# RSL15 register map
Vendor: ONSemiconductor; Series: RSL15 Series; File version: 1.0
CPU: CM33 r0p4, little endian, MPU, FPU, 3 interrupt priority bits
Registers are 32-bit, read-write, reset 0x0 unless marked. A register's access mark holds for its fields unless they carry their own. Offsets are from the block's base; [hi:lo] are bit positions.

## BBIF — Baseband Controller Interface
Base 0x40001800
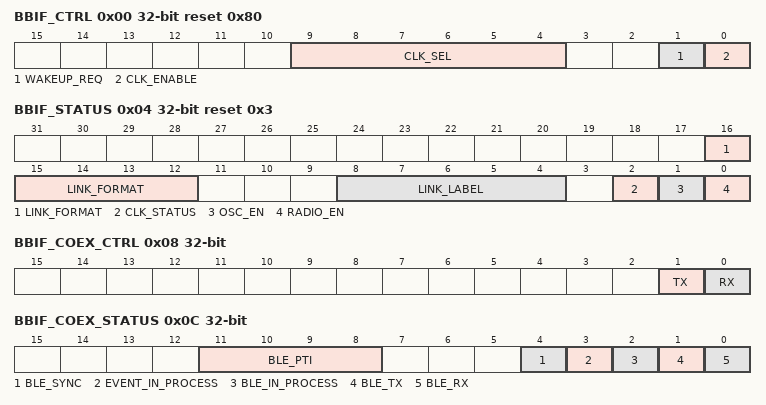
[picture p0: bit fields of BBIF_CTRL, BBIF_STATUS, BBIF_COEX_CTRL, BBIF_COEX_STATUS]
0x00 BBIF_CTRL reset 0x80 — Baseband controller control register
  [9:4] CLK_SEL — Configure the internal baseband controller clock divider in order to provide a 1MHz reference clock
    6=BBCLK_DIVIDER_6 (Divide the BBCLK by 6 (minimum authorized value)); 8=BBCLK_DIVIDER_8 (Divide the BBCLK by 8); 12=BBCLK_DIVIDER_12 (Divide the BBCLK by 12); 16=BBCLK_DIVIDER_16 (Divide the BBCLK by 16); 24=BBCLK_DIVIDER_24 (Divide the BBCLK by 24 (maximum authorized value))
  [1] WAKEUP_REQ — External wake up request used to sort-out sleep modes
    0=BB_DEEP_SLEEP (Keep the baseband controller in deep sleep mode); 1=BB_WAKEUP (Wake up the baseband controller and keep it active)
  [0] CLK_ENABLE — Enable the baseband controller clocks generation
    0=BB_CLK_DISABLE (Baseband controller clocks are gated); 1=BB_CLK_ENABLE (Baseband controller clocks are generated)
0x04 BBIF_STATUS ro reset 0x3 — Baseband controller status register
  [16:12] LINK_FORMAT — BLE link format
  [8:4] LINK_LABEL — BLE link label
  [2] CLK_STATUS — Clock status defining the current active clock in use
    0=MASTER_CLK (Baseband controller running on master1/2_clk); 1=LOW_POWER_CLK (Baseband controller running on low_power_clk)
  [1] OSC_EN — Oscillator front-end enabling
    0=OSC_DISABLED (Oscillator can be safely disabled); 1=OSC_ENABLED (Oscillator must be enabled)
  [0] RADIO_EN — RF front-end enabling
    0=RF_DISABLED (RF front-end can be safely disabled); 1=RF_ENABLED (RF front-end must be enabled)
0x08 BBIF_COEX_CTRL — Coexistence control register
  [1] TX — WLAN collocated device transmit active
    0=COEX_TX_IDLE (RF front-end has no non-BLE TX activity); 1=COEX_TX_BUSY (RF front-end performs a non-BLE TX activity)
  [0] RX — WLAN collocated device reception active
    0=COEX_RX_IDLE (RF front-end has no non-BLE RX activity); 1=COEX_RX_BUSY (RF front-end performs a non-BLE RX activity)
0x0C BBIF_COEX_STATUS ro — Coexistence status register
  [11:8] BLE_PTI — BLE packet traffic information
    0=BLE_PTI_PRIORITY_0 (BLE_PTI lowest priority); 15=BLE_PTI_PRIORITY_15 (BLE_PTI highest priority)
  [4] BLE_SYNC — BLE 625us timing pulse reference
    0=BLE_SYNC_IDLE (RW-BLE sync idle); 1=BLE_SYNC_BUSY (RW-BLE sync active)
  [3] EVENT_IN_PROCESS — BLE event status
    0=EVENT_IDLE (No BLE event is processed); 1=EVENT_IN_PROCESS (BLE event is processed)
  [2] BLE_IN_PROCESS — BLE in process indicator
    0=BLE_IDLE (RW-BLE processes no event); 1=BLE_IN_PROCESS (RW-BLE processes an event)
  [1] BLE_TX — BLE transmit indicator
    0=BLE_TX_IDLE (RW-BLE core performs no Tx activity); 1=BLE_TX_BUSY (RW-BLE core performs Tx activity)
  [0] BLE_RX — BLE reception indicator
    0=BLE_RX_IDLE (RW-BLE core performs no Rx activity); 1=BLE_RX_BUSY (RW-BLE core performs Rx activity)
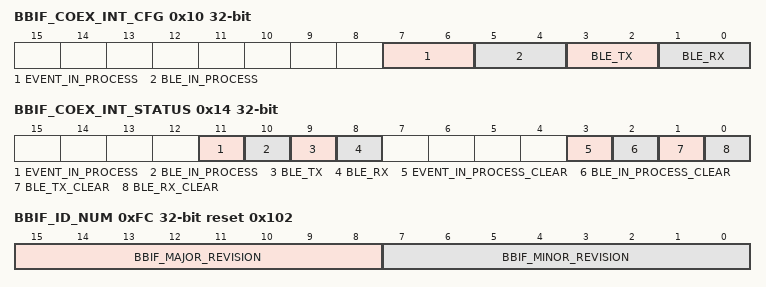
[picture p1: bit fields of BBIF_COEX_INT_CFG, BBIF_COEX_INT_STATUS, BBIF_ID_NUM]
0x10 BBIF_COEX_INT_CFG — Coexistence interrupts configuration register
  [7:6] EVENT_IN_PROCESS — EVENT_IN_PROCESS event interrupt configuration
    0=EVENT_IN_PROCESS_NONE (Interrupt not triggered); 1=EVENT_IN_PROCESS_RISING_EDGE (Interrupt triggered on rising edge); 2=EVENT_IN_PROCESS_FALLING_EDGE (Interrupt triggered on falling edge); 3=EVENT_IN_PROCESS_TRANSITION (Interrupt triggered on any edge)
  [5:4] BLE_IN_PROCESS — BLE_IN_PROCESS event interrupt configuration
    0=BLE_IN_PROCESS_NONE (Interrupt not triggered); 1=BLE_IN_PROCESS_RISING_EDGE (Interrupt triggered on rising edge); 2=BLE_IN_PROCESS_FALLING_EDGE (Interrupt triggered on falling edge); 3=BLE_IN_PROCESS_TRANSITION (Interrupt triggered on any edge)
  [3:2] BLE_TX — BLE_TX event interrupt configuration
    0=BLE_TX_NONE (Interrupt not triggered); 1=BLE_TX_RISING_EDGE (Interrupt triggered on rising edge); 2=BLE_TX_FALLING_EDGE (Interrupt triggered on falling edge); 3=BLE_TX_TRANSITION (Interrupt triggered on any edge)
  [1:0] BLE_RX — BLE_RX event interrupt configuration
    0=BLE_RX_NONE (Interrupt not triggered); 1=BLE_RX_RISING_EDGE (Interrupt triggered on rising edge); 2=BLE_RX_FALLING_EDGE (Interrupt triggered on falling edge); 3=BLE_RX_TRANSITION (Interrupt triggered on any edge)
0x14 BBIF_COEX_INT_STATUS (reset mask 0xF00) — Coexistence interrupt status register
  [11] EVENT_IN_PROCESS ro — EVENT_IN_PROCESS interrupt status flag
    0=EVENT_IN_PROCESS_NO_INT (No EVENT_IN_PROCESS_EVENT interrupt has been generated); 1=EVENT_IN_PROCESS_INT (A EVENT_IN_PROCESS_EVENT interrupt has been generated)
  [10] BLE_IN_PROCESS ro — BLE_IN_PROCESS interrupt status flag
    0=BLE_IN_PROCESS_NO_INT (No BLE_IN_PROCESS_EVENT interrupt has been generated); 1=BLE_IN_PROCESS_INT (A BLE_IN_PROCESS_EVENT interrupt has been generated)
  [9] BLE_TX ro — BLE_TX interrupt status flag
    0=BLE_TX_NO_INT (No BLE_TX_EVENT interrupt has been generated); 1=BLE_TX_INT (A BLE_TX_EVENT interrupt has been generated)
  [8] BLE_RX ro — BLE_RX interrupt status flag
    0=BLE_RX_NO_INT (No BLE_RX_EVENT interrupt has been generated); 1=BLE_RX_INT (A BLE_RX_EVENT interrupt has been generated)
  [3] EVENT_IN_PROCESS_CLEAR wo — Clear EVENT_IN_PROCESS status flag
    1=EVENT_IN_PROCESS_CLEAR
  [2] BLE_IN_PROCESS_CLEAR wo — Clear BLE_IN_PROCESS status flag
    1=BLE_IN_PROCESS_CLEAR
  [1] BLE_TX_CLEAR wo — Clear BLE_TX status flag
    1=BLE_TX_CLEAR
  [0] BLE_RX_CLEAR wo — Clear BLE_RX status flag
    1=BLE_RX_CLEAR
0xFC BBIF_ID_NUM ro reset 0x102 — Baseband controller interface ID number
  [15:8] BBIF_MAJOR_REVISION — Baseband controller interface Major Revision number
    1=BBIF_MAJOR_REVISION (Baseband controller interface revision 1.2)
  [7:0] BBIF_MINOR_REVISION — Baseband controller interface Minor Revision number
    2=BBIF_MINOR_REVISION (Baseband controller interface revision 1.2)
